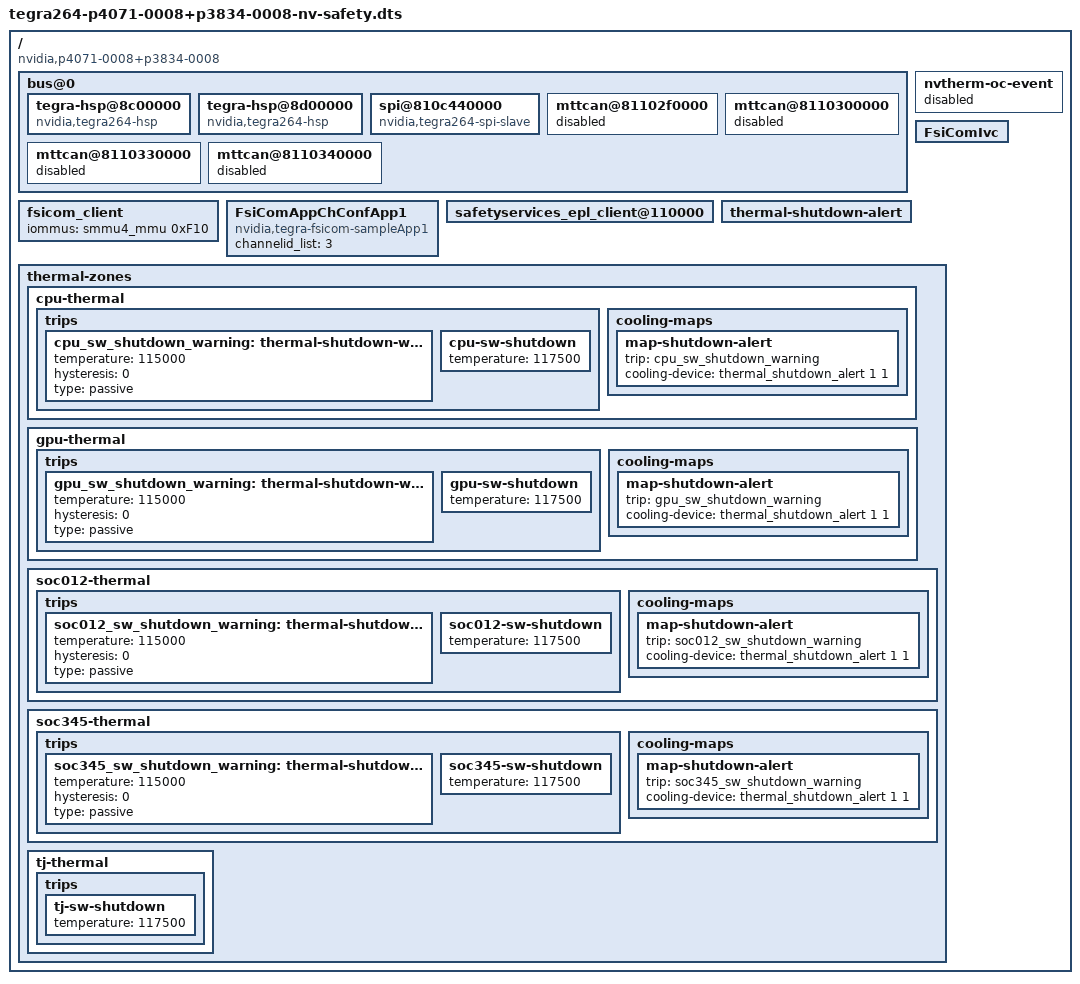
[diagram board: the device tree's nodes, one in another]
// SPDX-License-Identifier: GPL-2.0-only
// SPDX-FileCopyrightText: Copyright (c) 2025-2026, NVIDIA CORPORATION & AFFILIATES.  All rights reserved.
/dts-v1/;

#include "tegra264-p4071-0008+p3834-0008-nv.dts"
#include "nv-soc/tegra264-soc-thermal-slowdown-disable.dtsi"

/ {
	compatible = "nvidia,p4071-0008+p3834-0008", "safety", "nvidia,p3834-0008", "nvidia,tegra264";

	bus@0 {
		tegra-hsp@8c00000 {
			compatible = "nvidia,tegra264-hsp";
			status = "okay";
		};

		tegra-hsp@8d00000 {
			compatible = "nvidia,tegra264-hsp";
			status = "okay";
		};

		spi@810c440000 {
			status = "okay";
			compatible = "nvidia,tegra264-spi-slave";
		};

		mttcan@81102f0000 {
			status = "disabled";
		};

		mttcan@8110300000 {
			status = "disabled";
		};

		mttcan@8110330000 {
			status = "disabled";
		};

		mttcan@8110340000 {
			status = "disabled";
		};
	};

	nvtherm-oc-event {
		status = "disabled";
	};

	fsicom_client {
		status = "okay";
		iommus = <&smmu4_mmu 0xF10>;
	};

	FsiComIvc {
		status = "okay";
	};

	/* FSI<->CCPLEX Communication through DRAM Carveout demo app */
	FsiComAppChConfApp1 {
		compatible = "nvidia,tegra-fsicom-sampleApp1";
		status = "okay";
		channelid_list = <3>;
	};

	safetyservices_epl_client@110000 {
		status = "okay";
	};

	thermal-shutdown-alert {
		status = "okay";
	};

	thermal-zones {
		cpu-thermal {
			trips {
				cpu_sw_shutdown_warning: thermal-shutdown-warning {
					temperature = <115000>;
					hysteresis = <0>;
					type = "passive";
				};

				cpu-sw-shutdown {
					temperature = <117500>;
				};
			};

			cooling-maps {
				map-shutdown-alert {
					trip = <&cpu_sw_shutdown_warning>;
					cooling-device = <&thermal_shutdown_alert 1 1>;
				};
			};
		};

		gpu-thermal {
			trips {
				gpu_sw_shutdown_warning: thermal-shutdown-warning {
					temperature = <115000>;
					hysteresis = <0>;
					type = "passive";
				};

				gpu-sw-shutdown {
					temperature = <117500>;
				};
			};

			cooling-maps {
				map-shutdown-alert {
					trip = <&gpu_sw_shutdown_warning>;
					cooling-device = <&thermal_shutdown_alert 1 1>;
				};
			};
		};

		soc012-thermal {
			trips {
				soc012_sw_shutdown_warning: thermal-shutdown-warning {
					temperature = <115000>;
					hysteresis = <0>;
					type = "passive";
				};

				soc012-sw-shutdown {
					temperature = <117500>;
				};
			};

			cooling-maps {
				map-shutdown-alert {
					trip = <&soc012_sw_shutdown_warning>;
					cooling-device = <&thermal_shutdown_alert 1 1>;
				};
			};
		};

		soc345-thermal {
			trips {
				soc345_sw_shutdown_warning: thermal-shutdown-warning {
					temperature = <115000>;
					hysteresis = <0>;
					type = "passive";
				};

				soc345-sw-shutdown {
					temperature = <117500>;
				};
			};

			cooling-maps {
				map-shutdown-alert {
					trip = <&soc345_sw_shutdown_warning>;
					cooling-device = <&thermal_shutdown_alert 1 1>;
				};
			};
		};

		tj-thermal {
			trips {
				tj-sw-shutdown {
					temperature = <117500>;
				};
			};
		};
	};
};
